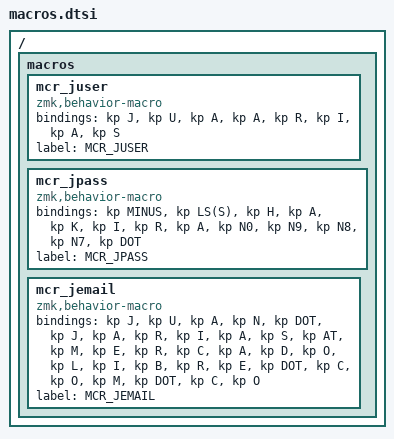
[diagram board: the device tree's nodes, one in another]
/*
 * Copyright (c) 2020 The ZMK Contributors
 *
 * SPDX-License-Identifier: MIT
 */


/ {
    macros {
        mcr_juser: mcr_juser {
            compatible = "zmk,behavior-macro";
            #binding-cells = <0>;
            bindings = <&kp J &kp U &kp A &kp A &kp R &kp I &kp A &kp S>;
            label = "MCR_JUSER";
        };

        mcr_jpass: mcr_jpass {
            compatible = "zmk,behavior-macro";
            #binding-cells = <0>;
            bindings = <&kp MINUS &kp LS(S) &kp H &kp A &kp K &kp I &kp R &kp A &kp N0 &kp N9 &kp N8 &kp N7 &kp DOT>;
            label = "MCR_JPASS";
        };

        mcr_jemail: mcr_jemail {
            compatible = "zmk,behavior-macro";
            #binding-cells = <0>;
            bindings = <&kp J &kp U &kp A &kp N &kp DOT &kp J &kp A &kp R &kp I &kp A &kp S &kp AT &kp M &kp E &kp R &kp C &kp A &kp D &kp O &kp L &kp I &kp B &kp R &kp E &kp DOT &kp C &kp O &kp M &kp DOT &kp C &kp O>;
            label = "MCR_JEMAIL";
        };

        //add your custom macros here
    };
};
